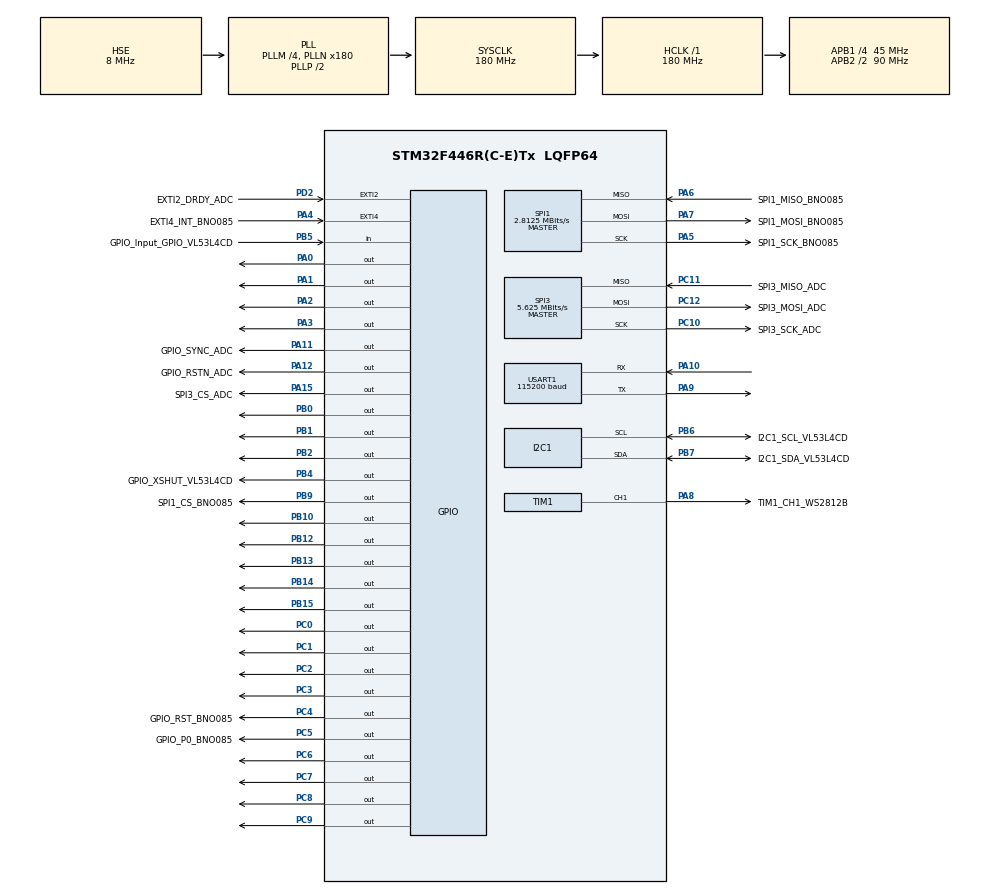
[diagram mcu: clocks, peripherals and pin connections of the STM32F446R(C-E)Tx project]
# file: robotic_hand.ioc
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Dma.Request0=TIM1_CH1
Dma.Request1=USART1_RX
Dma.Request2=USART1_TX
Dma.Request3=SPI1_RX
Dma.Request4=SPI3_RX
Dma.Request5=SPI3_TX
Dma.SPI1_RX.3.Direction=DMA_PERIPH_TO_MEMORY
Dma.SPI1_RX.3.FIFOMode=DMA_FIFOMODE_DISABLE
Dma.SPI1_RX.3.Instance=DMA2_Stream0
Dma.SPI1_RX.3.MemDataAlignment=DMA_MDATAALIGN_BYTE
Dma.SPI1_RX.3.MemInc=DMA_MINC_ENABLE
Dma.SPI1_RX.3.Mode=DMA_NORMAL
Dma.SPI1_RX.3.PeriphDataAlignment=DMA_PDATAALIGN_BYTE
Dma.SPI1_RX.3.PeriphInc=DMA_PINC_DISABLE
Dma.SPI1_RX.3.Priority=DMA_PRIORITY_LOW
Dma.SPI3_RX.4.Direction=DMA_PERIPH_TO_MEMORY
Dma.SPI3_RX.4.FIFOMode=DMA_FIFOMODE_DISABLE
Dma.SPI3_RX.4.Instance=DMA1_Stream0
Dma.SPI3_RX.4.MemDataAlignment=DMA_MDATAALIGN_BYTE
Dma.SPI3_RX.4.MemInc=DMA_MINC_ENABLE
Dma.SPI3_RX.4.Mode=DMA_NORMAL
Dma.SPI3_RX.4.PeriphDataAlignment=DMA_PDATAALIGN_BYTE
Dma.SPI3_RX.4.PeriphInc=DMA_PINC_DISABLE
Dma.SPI3_RX.4.Priority=DMA_PRIORITY_LOW
Dma.SPI3_TX.5.Direction=DMA_MEMORY_TO_PERIPH
Dma.SPI3_TX.5.FIFOMode=DMA_FIFOMODE_DISABLE
Dma.SPI3_TX.5.Instance=DMA1_Stream5
Dma.SPI3_TX.5.MemDataAlignment=DMA_MDATAALIGN_BYTE
Dma.SPI3_TX.5.MemInc=DMA_MINC_ENABLE
Dma.SPI3_TX.5.Mode=DMA_NORMAL
Dma.SPI3_TX.5.PeriphDataAlignment=DMA_PDATAALIGN_BYTE
Dma.SPI3_TX.5.PeriphInc=DMA_PINC_DISABLE
Dma.SPI3_TX.5.Priority=DMA_PRIORITY_LOW
Dma.TIM1_CH1.0.Direction=DMA_MEMORY_TO_PERIPH
Dma.TIM1_CH1.0.FIFOMode=DMA_FIFOMODE_DISABLE
Dma.TIM1_CH1.0.Instance=DMA2_Stream1
Dma.TIM1_CH1.0.MemDataAlignment=DMA_MDATAALIGN_HALFWORD
Dma.TIM1_CH1.0.MemInc=DMA_MINC_ENABLE
Dma.TIM1_CH1.0.Mode=DMA_NORMAL
Dma.TIM1_CH1.0.PeriphDataAlignment=DMA_PDATAALIGN_HALFWORD
Dma.TIM1_CH1.0.PeriphInc=DMA_PINC_DISABLE
Dma.TIM1_CH1.0.Priority=DMA_PRIORITY_LOW
Dma.USART1_RX.1.Direction=DMA_PERIPH_TO_MEMORY
Dma.USART1_RX.1.FIFOMode=DMA_FIFOMODE_DISABLE
Dma.USART1_RX.1.Instance=DMA2_Stream2
Dma.USART1_RX.1.MemDataAlignment=DMA_MDATAALIGN_BYTE
Dma.USART1_RX.1.MemInc=DMA_MINC_ENABLE
Dma.USART1_RX.1.Mode=DMA_CIRCULAR
Dma.USART1_RX.1.PeriphDataAlignment=DMA_PDATAALIGN_BYTE
Dma.USART1_RX.1.PeriphInc=DMA_PINC_DISABLE
Dma.USART1_RX.1.Priority=DMA_PRIORITY_LOW
Dma.USART1_TX.2.Direction=DMA_MEMORY_TO_PERIPH
Dma.USART1_TX.2.FIFOMode=DMA_FIFOMODE_DISABLE
Dma.USART1_TX.2.Instance=DMA2_Stream7
Dma.USART1_TX.2.MemDataAlignment=DMA_MDATAALIGN_BYTE
Dma.USART1_TX.2.MemInc=DMA_MINC_ENABLE
Dma.USART1_TX.2.Mode=DMA_NORMAL
Dma.USART1_TX.2.PeriphDataAlignment=DMA_PDATAALIGN_BYTE
Dma.USART1_TX.2.PeriphInc=DMA_PINC_DISABLE
Dma.USART1_TX.2.Priority=DMA_PRIORITY_LOW
Mcu.Family=STM32F4
Mcu.Name=STM32F446R(C-E)Tx
Mcu.Package=LQFP64
NVIC.DMA1_Stream0_IRQn=true\:0\:0\:false\:false\:true\:false\:true\:true
NVIC.DMA1_Stream5_IRQn=true\:0\:0\:false\:false\:true\:false\:true\:true
NVIC.DMA2_Stream0_IRQn=true\:0\:0\:false\:false\:true\:false\:true\:true
NVIC.DMA2_Stream1_IRQn=true\:0\:0\:false\:false\:true\:false\:true\:true
NVIC.DMA2_Stream2_IRQn=true\:0\:0\:false\:false\:true\:false\:true\:true
NVIC.DMA2_Stream7_IRQn=true\:0\:0\:false\:false\:true\:false\:true\:true
NVIC.EXTI2_IRQn=true\:0\:0\:false\:false\:true\:true\:true\:true
NVIC.PriorityGroup=NVIC_PRIORITYGROUP_0
NVIC.SPI1_IRQn=true\:0\:0\:false\:false\:true\:true\:true\:true
NVIC.USART1_IRQn=true\:0\:0\:false\:false\:true\:true\:true\:true
PA0-WKUP.Signal=GPIO_Output
PA1.Signal=GPIO_Output
PA10.Mode=Asynchronous
PA10.Signal=USART1_RX
PA11.GPIO_Label=GPIO_SYNC_ADC
PA11.PinState=GPIO_PIN_SET
PA11.Signal=GPIO_Output
PA12.GPIO_Label=GPIO_RSTN_ADC
PA12.PinState=GPIO_PIN_SET
PA12.Signal=GPIO_Output
PA13.GPIO_Label=SWDIO
PA13.Mode=Trace_Asynchronous_SW
PA13.Signal=SYS_JTMS-SWDIO
PA14.GPIO_Label=SWCLK
PA14.Mode=Trace_Asynchronous_SW
PA14.Signal=SYS_JTCK-SWCLK
PA15.GPIO_Label=SPI3_CS_ADC
PA15.Signal=GPIO_Output
PA2.Signal=GPIO_Output
PA3.Signal=GPIO_Output
PA4.GPIO_Label=EXTI4_INT_BNO085
PA4.GPIO_ModeDefaultEXTI=GPIO_MODE_EVT_FALLING
PA4.GPIO_PuPd=GPIO_PULLUP
PA4.Signal=GPXTI4
PA5.GPIO_Label=SPI1_SCK_BNO085
PA5.Mode=Full_Duplex_Master
PA5.Signal=SPI1_SCK
PA6.GPIO_Label=SPI1_MISO_BNO085
PA6.Mode=Full_Duplex_Master
PA6.Signal=SPI1_MISO
PA7.GPIO_Label=SPI1_MOSI_BNO085
PA7.Mode=Full_Duplex_Master
PA7.Signal=SPI1_MOSI
PA8.GPIO_Label=TIM1_CH1_WS2812B
PA8.Signal=S_TIM1_CH1
PA9.Mode=Asynchronous
PA9.Signal=USART1_TX
PB0.Signal=GPIO_Output
PB1.Signal=GPIO_Output
PB10.Signal=GPIO_Output
PB12.Signal=GPIO_Output
PB13.Signal=GPIO_Output
PB14.Signal=GPIO_Output
PB15.Signal=GPIO_Output
PB2.Signal=GPIO_Output
PB3.GPIO_Label=SWO
PB3.Mode=Trace_Asynchronous_SW
PB3.Signal=SYS_JTDO-SWO
PB4.GPIO_Label=GPIO_XSHUT_VL53L4CD
PB4.PinState=GPIO_PIN_SET
PB4.Signal=GPIO_Output
PB5.GPIO_Label=GPIO_Input_GPIO_VL53L4CD
PB5.Signal=GPIO_Input
PB6.GPIO_Label=I2C1_SCL_VL53L4CD
PB6.Mode=I2C
PB6.Signal=I2C1_SCL
PB7.GPIO_Label=I2C1_SDA_VL53L4CD
PB7.Mode=I2C
PB7.Signal=I2C1_SDA
PB9.GPIO_Label=SPI1_CS_BNO085
PB9.GPIO_PuPd=GPIO_PULLUP
PB9.PinState=GPIO_PIN_SET
PB9.Signal=GPIO_Output
PC0.Signal=GPIO_Output
PC1.Signal=GPIO_Output
PC10.GPIO_Label=SPI3_SCK_ADC
PC10.Mode=Full_Duplex_Master
PC10.Signal=SPI3_SCK
PC11.GPIO_Label=SPI3_MISO_ADC
PC11.Mode=Full_Duplex_Master
PC11.Signal=SPI3_MISO
PC12.GPIO_Label=SPI3_MOSI_ADC
PC12.Mode=Full_Duplex_Master
PC12.Signal=SPI3_MOSI
PC14-OSC32_IN.Signal=RCC_OSC32_IN
PC15-OSC32_OUT.Signal=RCC_OSC32_OUT
PC2.Signal=GPIO_Output
PC3.Signal=GPIO_Output
PC4.GPIO_Label=GPIO_RST_BNO085
PC4.Signal=GPIO_Output
PC5.GPIO_Label=GPIO_P0_BNO085
PC5.Signal=GPIO_Output
PC6.Signal=GPIO_Output
PC7.Signal=GPIO_Output
PC8.Signal=GPIO_Output
PC9.Signal=GPIO_Output
PD2.GPIO_Label=EXTI2_DRDY_ADC
PD2.GPIO_ModeDefaultEXTI=GPIO_MODE_IT_FALLING
PD2.Signal=GPXTI2
PH0-OSC_IN.Mode=HSE-External-Oscillator
PH0-OSC_IN.Signal=RCC_OSC_IN
PH1-OSC_OUT.Mode=HSE-External-Oscillator
PH1-OSC_OUT.Signal=RCC_OSC_OUT
ProjectManager.HeapSize=0x200
ProjectManager.StackSize=0x400
ProjectManager.TargetToolchain=STM32CubeIDE
RCC.48MHZClocksFreq_Value=84000000
RCC.AHBFreq_Value=180000000
RCC.APB1CLKDivider=RCC_HCLK_DIV4
RCC.APB1Freq_Value=45000000
RCC.APB1TimFreq_Value=90000000
RCC.APB2CLKDivider=RCC_HCLK_DIV2
RCC.APB2Freq_Value=90000000
RCC.APB2TimFreq_Value=180000000
RCC.CortexFreq_Value=180000000
RCC.FLatency-AdvancedSettings=FLASH_LATENCY_5
RCC.HCLKFreq_Value=180000000
RCC.HSE_VALUE=8000000
RCC.HSI_VALUE=16000000
RCC.PLLM=4
RCC.PLLN=180
RCC.PLLSourceVirtual=RCC_PLLSOURCE_HSE
RCC.SYSCLKFreq_VALUE=180000000
RCC.SYSCLKSource=RCC_SYSCLKSOURCE_PLLCLK
RCC.USBFreq_Value=180000000
RCC.VCOOutputFreq_Value=360000000
SH.S_TIM1_CH1.0=TIM1_CH1,PWM Generation1 CH1
SPI1.BaudRatePrescaler=SPI_BAUDRATEPRESCALER_32
SPI1.CLKPhase=SPI_PHASE_2EDGE
SPI1.CLKPolarity=SPI_POLARITY_HIGH
SPI1.CalculateBaudRate=2.8125 MBits/s
SPI1.Direction=SPI_DIRECTION_2LINES
SPI1.Mode=SPI_MODE_MASTER
SPI1.VirtualType=VM_MASTER
SPI3.BaudRatePrescaler=SPI_BAUDRATEPRESCALER_8
SPI3.CLKPhase=SPI_PHASE_2EDGE
SPI3.CalculateBaudRate=5.625 MBits/s
SPI3.Direction=SPI_DIRECTION_2LINES
SPI3.Mode=SPI_MODE_MASTER
SPI3.VirtualType=VM_MASTER
TIM1.Channel-PWM\ Generation1\ CH1=TIM_CHANNEL_1
TIM1.Period=25-1
TIM1.Prescaler=9-1
TIM5.Channel-PWM\ Generation1\ No\ Output=TIM_CHANNEL_1
TIM5.Prescaler=44
USART1.BaudRate=115200
USART1.VirtualMode=VM_ASYNC
VP_TIM5_VS_no_output1.Mode=PWM Generation1 No Output
board=NUCLEO-F446RE

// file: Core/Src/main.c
/* USER CODE BEGIN Header */
/**
  ******************************************************************************
  * @file           : main.c
  * @brief          : Main program body
  ******************************************************************************
  * @attention
  *
  * Copyright (c) 2025 STMicroelectronics.
  * All rights reserved.
  *
  * This software is licensed under terms that can be found in the LICENSE file
  * in the root directory of this software component.
  * If no LICENSE file comes with this software, it is provided AS-IS.
  *
  ******************************************************************************
  */
/* USER CODE END Header */
#include "main.h"

/* USER CODE BEGIN Includes */
#include "state_machine.h"
/* USER CODE END Includes */

I2C_HandleTypeDef hi2c1;

SPI_HandleTypeDef hspi1;
SPI_HandleTypeDef hspi3;
DMA_HandleTypeDef hdma_spi1_rx;
DMA_HandleTypeDef hdma_spi3_rx;
DMA_HandleTypeDef hdma_spi3_tx;

TIM_HandleTypeDef htim1;
TIM_HandleTypeDef htim5;
DMA_HandleTypeDef hdma_tim1_ch1;

UART_HandleTypeDef huart1;
DMA_HandleTypeDef hdma_usart1_rx;
DMA_HandleTypeDef hdma_usart1_tx;

void SystemClock_Config(void);
static void MX_GPIO_Init(void);
static void MX_DMA_Init(void);
static void MX_SPI1_Init(void);
static void MX_I2C1_Init(void);
static void MX_SPI3_Init(void);
static void MX_TIM1_Init(void);
static void MX_USART1_UART_Init(void);
static void MX_TIM5_Init(void);

int main(void)
{

  /* MCU Configuration--------------------------------------------------------*/

  /* Reset of all peripherals, Initializes the Flash interface and the Systick. */
  HAL_Init();

  /* Configure the system clock */
  SystemClock_Config();

  /* Initialize all configured peripherals */
  MX_GPIO_Init();
  MX_DMA_Init();
  MX_SPI1_Init();
  MX_I2C1_Init();
  MX_SPI3_Init();
  MX_TIM1_Init();
  MX_USART1_UART_Init();
  MX_TIM5_Init();

  /* Infinite loop */
  /* USER CODE BEGIN WHILE */
  while (1) {
    run_state_machine();
    /* USER CODE END WHILE */

  }
}

void SystemClock_Config(void)
{
  RCC_OscInitTypeDef RCC_OscInitStruct = {0};
  RCC_ClkInitTypeDef RCC_ClkInitStruct = {0};

  /** Configure the main internal regulator output voltage
  */
  __HAL_RCC_PWR_CLK_ENABLE();
  __HAL_PWR_VOLTAGESCALING_CONFIG(PWR_REGULATOR_VOLTAGE_SCALE1);

  /** Initializes the RCC Oscillators according to the specified parameters
  * in the RCC_OscInitTypeDef structure.
  */
  RCC_OscInitStruct.OscillatorType = RCC_OSCILLATORTYPE_HSE;
  RCC_OscInitStruct.HSEState = RCC_HSE_ON;
  RCC_OscInitStruct.PLL.PLLState = RCC_PLL_ON;
  RCC_OscInitStruct.PLL.PLLSource = RCC_PLLSOURCE_HSE;
  RCC_OscInitStruct.PLL.PLLM = 4;
  RCC_OscInitStruct.PLL.PLLN = 180;
  RCC_OscInitStruct.PLL.PLLP = RCC_PLLP_DIV2;
  RCC_OscInitStruct.PLL.PLLQ = 2;
  RCC_OscInitStruct.PLL.PLLR = 2;
  if (HAL_RCC_OscConfig(&RCC_OscInitStruct) != HAL_OK)
  {
    Error_Handler();
  }

  /** Activate the Over-Drive mode
  */
  if (HAL_PWREx_EnableOverDrive() != HAL_OK)
  {
    Error_Handler();
  }

  /** Initializes the CPU, AHB and APB buses clocks
  */
  RCC_ClkInitStruct.ClockType = RCC_CLOCKTYPE_HCLK|RCC_CLOCKTYPE_SYSCLK
                              |RCC_CLOCKTYPE_PCLK1|RCC_CLOCKTYPE_PCLK2;
  RCC_ClkInitStruct.SYSCLKSource = RCC_SYSCLKSOURCE_PLLCLK;
  RCC_ClkInitStruct.AHBCLKDivider = RCC_SYSCLK_DIV1;
  RCC_ClkInitStruct.APB1CLKDivider = RCC_HCLK_DIV4;
  RCC_ClkInitStruct.APB2CLKDivider = RCC_HCLK_DIV2;

  if (HAL_RCC_ClockConfig(&RCC_ClkInitStruct, FLASH_LATENCY_5) != HAL_OK)
  {
    Error_Handler();
  }
}

static void MX_I2C1_Init(void)
{

  hi2c1.Instance = I2C1;
  hi2c1.Init.ClockSpeed = 100000;
  hi2c1.Init.DutyCycle = I2C_DUTYCYCLE_2;
  hi2c1.Init.OwnAddress1 = 0;
  hi2c1.Init.AddressingMode = I2C_ADDRESSINGMODE_7BIT;
  hi2c1.Init.DualAddressMode = I2C_DUALADDRESS_DISABLE;
  hi2c1.Init.OwnAddress2 = 0;
  hi2c1.Init.GeneralCallMode = I2C_GENERALCALL_DISABLE;
  hi2c1.Init.NoStretchMode = I2C_NOSTRETCH_DISABLE;
  if (HAL_I2C_Init(&hi2c1) != HAL_OK)
  {
    Error_Handler();
  }

}

static void MX_SPI1_Init(void)
{

  /* SPI1 parameter configuration*/
  hspi1.Instance = SPI1;
  hspi1.Init.Mode = SPI_MODE_MASTER;
  hspi1.Init.Direction = SPI_DIRECTION_2LINES;
  hspi1.Init.DataSize = SPI_DATASIZE_8BIT;
  hspi1.Init.CLKPolarity = SPI_POLARITY_HIGH;
  hspi1.Init.CLKPhase = SPI_PHASE_2EDGE;
  hspi1.Init.NSS = SPI_NSS_SOFT;
  hspi1.Init.BaudRatePrescaler = SPI_BAUDRATEPRESCALER_32;
  hspi1.Init.FirstBit = SPI_FIRSTBIT_MSB;
  hspi1.Init.TIMode = SPI_TIMODE_DISABLE;
  hspi1.Init.CRCCalculation = SPI_CRCCALCULATION_DISABLE;
  hspi1.Init.CRCPolynomial = 10;
  if (HAL_SPI_Init(&hspi1) != HAL_OK)
  {
    Error_Handler();
  }

}

static void MX_SPI3_Init(void)
{

  /* SPI3 parameter configuration*/
  hspi3.Instance = SPI3;
  hspi3.Init.Mode = SPI_MODE_MASTER;
  hspi3.Init.Direction = SPI_DIRECTION_2LINES;
  hspi3.Init.DataSize = SPI_DATASIZE_8BIT;
  hspi3.Init.CLKPolarity = SPI_POLARITY_LOW;
  hspi3.Init.CLKPhase = SPI_PHASE_2EDGE;
  hspi3.Init.NSS = SPI_NSS_SOFT;
  hspi3.Init.BaudRatePrescaler = SPI_BAUDRATEPRESCALER_8;
  hspi3.Init.FirstBit = SPI_FIRSTBIT_MSB;
  hspi3.Init.TIMode = SPI_TIMODE_DISABLE;
  hspi3.Init.CRCCalculation = SPI_CRCCALCULATION_DISABLE;
  hspi3.Init.CRCPolynomial = 10;
  if (HAL_SPI_Init(&hspi3) != HAL_OK)
  {
    Error_Handler();
  }

}

static void MX_TIM1_Init(void)
{

  TIM_MasterConfigTypeDef sMasterConfig = {0};
  TIM_OC_InitTypeDef sConfigOC = {0};
  TIM_BreakDeadTimeConfigTypeDef sBreakDeadTimeConfig = {0};

  htim1.Instance = TIM1;
  htim1.Init.Prescaler = 9-1;
  htim1.Init.CounterMode = TIM_COUNTERMODE_UP;
  htim1.Init.Period = 25-1;
  htim1.Init.ClockDivision = TIM_CLOCKDIVISION_DIV1;
  htim1.Init.RepetitionCounter = 0;
  htim1.Init.AutoReloadPreload = TIM_AUTORELOAD_PRELOAD_DISABLE;
  if (HAL_TIM_PWM_Init(&htim1) != HAL_OK)
  {
    Error_Handler();
  }
  sMasterConfig.MasterOutputTrigger = TIM_TRGO_RESET;
  sMasterConfig.MasterSlaveMode = TIM_MASTERSLAVEMODE_DISABLE;
  if (HAL_TIMEx_MasterConfigSynchronization(&htim1, &sMasterConfig) != HAL_OK)
  {
    Error_Handler();
  }
  sConfigOC.OCMode = TIM_OCMODE_PWM1;
  sConfigOC.Pulse = 0;
  sConfigOC.OCPolarity = TIM_OCPOLARITY_HIGH;
  sConfigOC.OCNPolarity = TIM_OCNPOLARITY_HIGH;
  sConfigOC.OCFastMode = TIM_OCFAST_DISABLE;
  sConfigOC.OCIdleState = TIM_OCIDLESTATE_RESET;
  sConfigOC.OCNIdleState = TIM_OCNIDLESTATE_RESET;
  if (HAL_TIM_PWM_ConfigChannel(&htim1, &sConfigOC, TIM_CHANNEL_1) != HAL_OK)
  {
    Error_Handler();
  }
  sBreakDeadTimeConfig.OffStateRunMode = TIM_OSSR_DISABLE;
  sBreakDeadTimeConfig.OffStateIDLEMode = TIM_OSSI_DISABLE;
  sBreakDeadTimeConfig.LockLevel = TIM_LOCKLEVEL_OFF;
  sBreakDeadTimeConfig.DeadTime = 0;
  sBreakDeadTimeConfig.BreakState = TIM_BREAK_DISABLE;
  sBreakDeadTimeConfig.BreakPolarity = TIM_BREAKPOLARITY_HIGH;
  sBreakDeadTimeConfig.AutomaticOutput = TIM_AUTOMATICOUTPUT_DISABLE;
  if (HAL_TIMEx_ConfigBreakDeadTime(&htim1, &sBreakDeadTimeConfig) != HAL_OK)
  {
    Error_Handler();
  }
  HAL_TIM_MspPostInit(&htim1);

}

static void MX_TIM5_Init(void)
{

  TIM_MasterConfigTypeDef sMasterConfig = {0};
  TIM_OC_InitTypeDef sConfigOC = {0};

  htim5.Instance = TIM5;
  htim5.Init.Prescaler = 44;
  htim5.Init.CounterMode = TIM_COUNTERMODE_UP;
  htim5.Init.Period = 4294967295;
  htim5.Init.ClockDivision = TIM_CLOCKDIVISION_DIV1;
  htim5.Init.AutoReloadPreload = TIM_AUTORELOAD_PRELOAD_DISABLE;
  if (HAL_TIM_PWM_Init(&htim5) != HAL_OK)
  {
    Error_Handler();
  }
  sMasterConfig.MasterOutputTrigger = TIM_TRGO_RESET;
  sMasterConfig.MasterSlaveMode = TIM_MASTERSLAVEMODE_DISABLE;
  if (HAL_TIMEx_MasterConfigSynchronization(&htim5, &sMasterConfig) != HAL_OK)
  {
    Error_Handler();
  }
  sConfigOC.OCMode = TIM_OCMODE_PWM1;
  sConfigOC.Pulse = 0;
  sConfigOC.OCPolarity = TIM_OCPOLARITY_HIGH;
  sConfigOC.OCFastMode = TIM_OCFAST_DISABLE;
  if (HAL_TIM_PWM_ConfigChannel(&htim5, &sConfigOC, TIM_CHANNEL_1) != HAL_OK)
  {
    Error_Handler();
  }

}

static void MX_USART1_UART_Init(void)
{

  huart1.Instance = USART1;
  huart1.Init.BaudRate = 115200;
  huart1.Init.WordLength = UART_WORDLENGTH_8B;
  huart1.Init.StopBits = UART_STOPBITS_1;
  huart1.Init.Parity = UART_PARITY_NONE;
  huart1.Init.Mode = UART_MODE_TX_RX;
  huart1.Init.HwFlowCtl = UART_HWCONTROL_NONE;
  huart1.Init.OverSampling = UART_OVERSAMPLING_16;
  if (HAL_UART_Init(&huart1) != HAL_OK)
  {
    Error_Handler();
  }

}

static void MX_DMA_Init(void)
{

  /* DMA controller clock enable */
  __HAL_RCC_DMA2_CLK_ENABLE();
  __HAL_RCC_DMA1_CLK_ENABLE();

  /* DMA interrupt init */
  /* DMA1_Stream0_IRQn interrupt configuration */
  HAL_NVIC_SetPriority(DMA1_Stream0_IRQn, 0, 0);
  HAL_NVIC_EnableIRQ(DMA1_Stream0_IRQn);
  /* DMA1_Stream5_IRQn interrupt configuration */
  HAL_NVIC_SetPriority(DMA1_Stream5_IRQn, 0, 0);
  HAL_NVIC_EnableIRQ(DMA1_Stream5_IRQn);
  /* DMA2_Stream0_IRQn interrupt configuration */
  HAL_NVIC_SetPriority(DMA2_Stream0_IRQn, 0, 0);
  HAL_NVIC_EnableIRQ(DMA2_Stream0_IRQn);
  /* DMA2_Stream1_IRQn interrupt configuration */
  HAL_NVIC_SetPriority(DMA2_Stream1_IRQn, 0, 0);
  HAL_NVIC_EnableIRQ(DMA2_Stream1_IRQn);
  /* DMA2_Stream2_IRQn interrupt configuration */
  HAL_NVIC_SetPriority(DMA2_Stream2_IRQn, 0, 0);
  HAL_NVIC_EnableIRQ(DMA2_Stream2_IRQn);
  /* DMA2_Stream7_IRQn interrupt configuration */
  HAL_NVIC_SetPriority(DMA2_Stream7_IRQn, 0, 0);
  HAL_NVIC_EnableIRQ(DMA2_Stream7_IRQn);

}

static void MX_GPIO_Init(void)
{
  GPIO_InitTypeDef GPIO_InitStruct = {0};

  /* GPIO Ports Clock Enable */
  __HAL_RCC_GPIOC_CLK_ENABLE();
  __HAL_RCC_GPIOH_CLK_ENABLE();
  __HAL_RCC_GPIOA_CLK_ENABLE();
  __HAL_RCC_GPIOB_CLK_ENABLE();
  __HAL_RCC_GPIOD_CLK_ENABLE();

  /*Configure GPIO pin Output Level */
  HAL_GPIO_WritePin(GPIOC, GPIO_PIN_0|GPIO_PIN_1|GPIO_PIN_2|GPIO_PIN_3
                          |GPIO_RST_BNO085_Pin|GPIO_P0_BNO085_Pin|GPIO_PIN_6|GPIO_PIN_7
                          |GPIO_PIN_8|GPIO_PIN_9, GPIO_PIN_RESET);

  /*Configure GPIO pin Output Level */
  HAL_GPIO_WritePin(GPIOA, GPIO_PIN_0|GPIO_PIN_1|GPIO_PIN_2|GPIO_PIN_3
                          |SPI3_CS_ADC_Pin, GPIO_PIN_RESET);

  /*Configure GPIO pin Output Level */
  HAL_GPIO_WritePin(GPIOB, GPIO_PIN_0|GPIO_PIN_1|GPIO_PIN_2|GPIO_PIN_10
                          |GPIO_PIN_12|GPIO_PIN_13|GPIO_PIN_14|GPIO_PIN_15, GPIO_PIN_RESET);

  /*Configure GPIO pin Output Level */
  HAL_GPIO_WritePin(GPIOA, GPIO_SYNC_ADC_Pin|GPIO_RSTN_ADC_Pin, GPIO_PIN_SET);

  /*Configure GPIO pin Output Level */
  HAL_GPIO_WritePin(GPIOB, GPIO_XSHUT_VL53L4CD_Pin|SPI1_CS_BNO085_Pin, GPIO_PIN_SET);

  /*Configure GPIO pins : PC0 PC1 PC2 PC3
                           GPIO_RST_BNO085_Pin GPIO_P0_BNO085_Pin PC6 PC7
                           PC8 PC9 */
  GPIO_InitStruct.Pin = GPIO_PIN_0|GPIO_PIN_1|GPIO_PIN_2|GPIO_PIN_3
                          |GPIO_RST_BNO085_Pin|GPIO_P0_BNO085_Pin|GPIO_PIN_6|GPIO_PIN_7
                          |GPIO_PIN_8|GPIO_PIN_9;
  GPIO_InitStruct.Mode = GPIO_MODE_OUTPUT_PP;
  GPIO_InitStruct.Pull = GPIO_NOPULL;
  GPIO_InitStruct.Speed = GPIO_SPEED_FREQ_LOW;
  HAL_GPIO_Init(GPIOC, &GPIO_InitStruct);

  /*Configure GPIO pins : PA0 PA1 PA2 PA3
                           GPIO_SYNC_ADC_Pin GPIO_RSTN_ADC_Pin SPI3_CS_ADC_Pin */
  GPIO_InitStruct.Pin = GPIO_PIN_0|GPIO_PIN_1|GPIO_PIN_2|GPIO_PIN_3
                          |GPIO_SYNC_ADC_Pin|GPIO_RSTN_ADC_Pin|SPI3_CS_ADC_Pin;
  GPIO_InitStruct.Mode = GPIO_MODE_OUTPUT_PP;
  GPIO_InitStruct.Pull = GPIO_NOPULL;
  GPIO_InitStruct.Speed = GPIO_SPEED_FREQ_LOW;
  HAL_GPIO_Init(GPIOA, &GPIO_InitStruct);

  /*Configure GPIO pin : EXTI4_INT_BNO085_Pin */
  GPIO_InitStruct.Pin = EXTI4_INT_BNO085_Pin;
  GPIO_InitStruct.Mode = GPIO_MODE_EVT_FALLING;
  GPIO_InitStruct.Pull = GPIO_PULLUP;
  HAL_GPIO_Init(EXTI4_INT_BNO085_GPIO_Port, &GPIO_InitStruct);

  /*Configure GPIO pins : PB0 PB1 PB2 PB10
                           PB12 PB13 PB14 PB15
                           GPIO_XSHUT_VL53L4CD_Pin */
  GPIO_InitStruct.Pin = GPIO_PIN_0|GPIO_PIN_1|GPIO_PIN_2|GPIO_PIN_10
                          |GPIO_PIN_12|GPIO_PIN_13|GPIO_PIN_14|GPIO_PIN_15
                          |GPIO_XSHUT_VL53L4CD_Pin;
  GPIO_InitStruct.Mode = GPIO_MODE_OUTPUT_PP;
  GPIO_InitStruct.Pull = GPIO_NOPULL;
  GPIO_InitStruct.Speed = GPIO_SPEED_FREQ_LOW;
  HAL_GPIO_Init(GPIOB, &GPIO_InitStruct);

  /*Configure GPIO pin : EXTI2_DRDY_ADC_Pin */
  GPIO_InitStruct.Pin = EXTI2_DRDY_ADC_Pin;
  GPIO_InitStruct.Mode = GPIO_MODE_IT_FALLING;
  GPIO_InitStruct.Pull = GPIO_NOPULL;
  HAL_GPIO_Init(EXTI2_DRDY_ADC_GPIO_Port, &GPIO_InitStruct);

  /*Configure GPIO pin : GPIO_Input_GPIO_VL53L4CD_Pin */
  GPIO_InitStruct.Pin = GPIO_Input_GPIO_VL53L4CD_Pin;
  GPIO_InitStruct.Mode = GPIO_MODE_INPUT;
  GPIO_InitStruct.Pull = GPIO_NOPULL;
  HAL_GPIO_Init(GPIO_Input_GPIO_VL53L4CD_GPIO_Port, &GPIO_InitStruct);

  /*Configure GPIO pin : SPI1_CS_BNO085_Pin */
  GPIO_InitStruct.Pin = SPI1_CS_BNO085_Pin;
  GPIO_InitStruct.Mode = GPIO_MODE_OUTPUT_PP;
  GPIO_InitStruct.Pull = GPIO_PULLUP;
  GPIO_InitStruct.Speed = GPIO_SPEED_FREQ_LOW;
  HAL_GPIO_Init(SPI1_CS_BNO085_GPIO_Port, &GPIO_InitStruct);

  /* EXTI interrupt init*/
  HAL_NVIC_SetPriority(EXTI2_IRQn, 0, 0);
  HAL_NVIC_EnableIRQ(EXTI2_IRQn);

}

void Error_Handler(void)
{
  __disable_irq();
  while (1)
  {
  }
}
